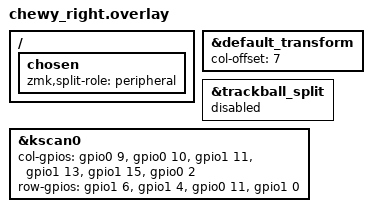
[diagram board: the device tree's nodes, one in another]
#include "chewy.dtsi"
#include <dt-bindings/zmk/input_transform.h>
#include <zephyr/dt-bindings/input/input-event-codes.h>

/ {
    chosen {
        zmk,split-role = "peripheral";
    };
};

&default_transform {
    col-offset = <7>;
};

&trackball_split {
    status = "disabled";
};

&kscan0 {
    col-gpios
        = <&gpio0 9 GPIO_ACTIVE_HIGH>
        , <&gpio0 10 GPIO_ACTIVE_HIGH>
        , <&gpio1 11 GPIO_ACTIVE_HIGH>
        , <&gpio1 13 GPIO_ACTIVE_HIGH>
        , <&gpio1 15 GPIO_ACTIVE_HIGH>
        , <&gpio0 2 GPIO_ACTIVE_HIGH>
        ;
        
    row-gpios
        = <&gpio1 6 (GPIO_ACTIVE_HIGH | GPIO_PULL_DOWN)>
        , <&gpio1 4 (GPIO_ACTIVE_HIGH | GPIO_PULL_DOWN)>
        , <&gpio0 11 (GPIO_ACTIVE_HIGH | GPIO_PULL_DOWN)>
        , <&gpio1 0 (GPIO_ACTIVE_HIGH | GPIO_PULL_DOWN)>
        ;
};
